AUTOSAR XML (schema 4-1-3)
standard types defined: boolean, sint16, uint16, uint8
package /UAES/ASW/ApplicationDataTypes
  6 x app type, all with category=CURVE, sw-calibration-access=READ-WRITE, compu {identical}:
    Appl_HvacBlowr_ratLPMBlowrCnv_CUR: sw-calprm-axis-set={sw-axis-index=1, category=COM_AXIS, sw-axis-individual={compu {identical}, sw-max-axis-points=3, sw-min-axis-points=3, range raw 0..255}}, range raw 0..65535
    Appl_HvacBlowr_ratPWMBlowrCnv_CUR: sw-calprm-axis-set={sw-axis-index=1, category=COM_AXIS, sw-axis-individual={compu {identical}, sw-max-axis-points=3, sw-min-axis-points=3, range raw 0..255}}, range raw 0..255
    Appl_HvacBlowr_ratReLPMBlowrCnv_CUR: sw-calprm-axis-set={sw-axis-index=1, category=COM_AXIS, sw-axis-individual={compu {identical}, sw-max-axis-points=3, sw-min-axis-points=3, range raw 0..255}}, range raw 0..65535
    Appl_HvacBlowr_ratRePWMBlowrCnv_CUR: sw-calprm-axis-set={sw-axis-index=1, category=COM_AXIS, sw-axis-individual={compu {identical}, sw-max-axis-points=3, sw-min-axis-points=3, range raw 0..255}}, range raw 0..255
    Appl_HvacBlowr_stLvlLPMBlowrCnv_CUR: sw-calprm-axis-set={sw-axis-index=1, category=COM_AXIS, sw-axis-individual={compu {identical}, sw-max-axis-points=3, sw-min-axis-points=3, range raw 0..65535}}, range raw 0..255
    Appl_HvacBlowr_stLvlReLPMBlowrCnv_CUR: sw-calprm-axis-set={sw-axis-index=1, category=COM_AXIS, sw-axis-individual={compu {identical}, sw-max-axis-points=3, sw-min-axis-points=3, range raw 0..65535}}, range raw 0..255
package /UAES/ASW/CompuMethods
  compu method CM_boolean: 0=FALSE, 1=TRUE
package /UAES/ASW/DataConstrs
  range DC_boolean: raw 0..1
  range DC_sint16: raw -32768..32767
package /UAES/ASW/DataTypeMappingSets
  data type mapping set DTMS_HvacBlowr_Ctrl
    data-type-maps:
      application-data-type=Appl_HvacBlowr_ratLPMBlowrCnv_CUR, implementation-data-type=HvacBlowr_ratLPMBlowrCnv_CUR_Type
      application-data-type=Appl_HvacBlowr_ratPWMBlowrCnv_CUR, implementation-data-type=HvacBlowr_ratPWMBlowrCnv_CUR_Type
      application-data-type=Appl_HvacBlowr_ratReLPMBlowrCnv_CUR, implementation-data-type=HvacBlowr_ratReLPMBlowrCnv_CUR_Type
      application-data-type=Appl_HvacBlowr_ratRePWMBlowrCnv_CUR, implementation-data-type=HvacBlowr_ratRePWMBlowrCnv_CUR_Type
      application-data-type=Appl_HvacBlowr_stLvlLPMBlowrCnv_CUR, implementation-data-type=HvacBlowr_stLvlLPMBlowrCnv_CUR_Type
      application-data-type=Appl_HvacBlowr_stLvlReLPMBlowrCnv_CUR, implementation-data-type=HvacBlowr_stLvlReLPMBlowrCnv_CUR_Type
package /UAES/ASW/ImplementationDataTypes
  8 x impl type:
    HvacBlowr_ratLPMBlowrCnv_CUR_Type: category=STRUCTURE
      element N1: implementation-data-type=uint8
      element BP1: implementation-data-type=rt_Array_uint8_3
      element Table: implementation-data-type=rt_Array_uint16_3
    HvacBlowr_ratPWMBlowrCnv_CUR_Type: category=STRUCTURE
      element N1: implementation-data-type=uint8
      element BP1: implementation-data-type=rt_Array_uint8_3
      element Table: implementation-data-type=rt_Array_uint8_3
    HvacBlowr_ratReLPMBlowrCnv_CUR_Type: category=STRUCTURE
      element N1: implementation-data-type=uint8
      element BP1: implementation-data-type=rt_Array_uint8_3
      element Table: implementation-data-type=rt_Array_uint16_3
    HvacBlowr_ratRePWMBlowrCnv_CUR_Type: category=STRUCTURE
      element N1: implementation-data-type=uint8
      element BP1: implementation-data-type=rt_Array_uint8_3
      element Table: implementation-data-type=rt_Array_uint8_3
    HvacBlowr_stLvlLPMBlowrCnv_CUR_Type: category=STRUCTURE
      element N1: implementation-data-type=uint16
      element BP1: implementation-data-type=rt_Array_uint16_3
      element Table: implementation-data-type=rt_Array_uint8_3
    HvacBlowr_stLvlReLPMBlowrCnv_CUR_Type: category=STRUCTURE
      element N1: implementation-data-type=uint16
      element BP1: implementation-data-type=rt_Array_uint16_3
      element Table: implementation-data-type=rt_Array_uint8_3
    rt_Array_uint16_3: category=ARRAY
      element rt_Array_uint16_3: array-size=3, array-size-semantics=FIXED-SIZE, implementation-data-type=uint16
    rt_Array_uint8_3: category=ARRAY
      element rt_Array_uint8_3: array-size=3, array-size-semantics=FIXED-SIZE, implementation-data-type=uint8
package /UAES/ASW/ImplementationDataTypes/Ground
  9 x constant specification:
    HvacBlowr_freqPWMBlowr1_C: value-spec=BLOWER_FREQUENCY_SPEC1:500
    HvacBlowr_freqPWMBlowr2_C: value-spec=BLOWER_FREQUENCY_SPEC1:100
    HvacBlowr_freqPWMBlowr3_C: value-spec=BLOWER_FREQUENCY_SPEC1:35
    HvacBlowr_ratLPMBlowrCnv_CUR: value-spec=fields=[N:3, X:[0, 1, 31], Y:[0, 230, 950]]
    HvacBlowr_ratPWMBlowrCnv_CUR: value-spec=fields=[N:3, X:[0, 1, 31], Y:[0, 23, 85]]
    HvacBlowr_ratReLPMBlowrCnv_CUR: value-spec=fields=[N:3, X:[0, 1, 31], Y:[0, 230, 950]]
    HvacBlowr_ratRePWMBlowrCnv_CUR: value-spec=fields=[N:3, X:[0, 1, 31], Y:[0, 23, 85]]
    HvacBlowr_stLvlLPMBlowrCnv_CUR: value-spec=fields=[N:3, X:[0, 350, 1350], Y:[0, 1, 31]]
    HvacBlowr_stLvlReLPMBlowrCnv_CUR: value-spec=fields=[N:3, X:[0, 350, 1350], Y:[0, 1, 31]]
package /UAES/ASW/PortInterfaces
  client server interface IoHwAb_IoSigAdc
    operation Adc_Get: possible-error=E_NOT_OK
      arg id_u16: type=uint16, direction=IN, server-argument-impl-policy=USE-ARGUMENT-TYPE
      arg val_s16: type=sint16, direction=OUT, server-argument-impl-policy=USE-ARGUMENT-TYPE
    operation AdcFac_Get: possible-error=E_NOT_OK
      arg id_u16: type=uint16, direction=IN, server-argument-impl-policy=USE-ARGUMENT-TYPE
      arg val_s16: type=sint16, direction=OUT, server-argument-impl-policy=USE-ARGUMENT-TYPE
    operation AdcVRMBatt_Get: possible-error=E_NOT_OK
      arg id_u16: type=uint16, direction=IN, server-argument-impl-policy=USE-ARGUMENT-TYPE
      arg val_u8: type=uint8, direction=OUT, server-argument-impl-policy=USE-ARGUMENT-TYPE
    error E_NOT_OK: error-code=1
  20 x sender receiver interface:
    gCFG_u8BlowrCtrlFreqTyp: invalidation-policy{data-element=gCFG_u8BlowrCtrlFreqTyp/Val, handle-invalid=DONT-INVALIDATE}
      data Val: sw-calibration-access=READ-ONLY, type=uint8
    gCFG_u8BlowrCtrlTyp: invalidation-policy{data-element=gCFG_u8BlowrCtrlTyp/Val, handle-invalid=DONT-INVALIDATE}
      data Val: sw-calibration-access=READ-ONLY, type=uint8
    gCFG_u8ReBlowrCtrlFreqTyp: invalidation-policy{data-element=gCFG_u8ReBlowrCtrlFreqTyp/Val, handle-invalid=DONT-INVALIDATE}
      data Val: sw-calibration-access=READ-ONLY, type=uint8
    gCFG_u8ReBlowrCtrlTyp: invalidation-policy{data-element=gCFG_u8ReBlowrCtrlTyp/Val, handle-invalid=DONT-INVALIDATE}
      data Val: sw-calibration-access=READ-ONLY, type=uint8
    gPRM_u8VehicleTypeCfg: invalidation-policy{data-element=gPRM_u8VehicleTypeCfg/Val, handle-invalid=DONT-INVALIDATE}
      data Val: sw-calibration-access=READ-ONLY, range raw 0..255, type=uint8
    HvacBlowr_bLPMBlowrEna: invalidation-policy{data-element=HvacBlowr_bLPMBlowrEna/Val, handle-invalid=DONT-INVALIDATE}
      data Val: sw-calibration-access=READ-ONLY, type=boolean
    HvacBlowr_bReLPMBlowrEna: invalidation-policy{data-element=HvacBlowr_bReLPMBlowrEna/Val, handle-invalid=DONT-INVALIDATE}
      data Val: sw-calibration-access=READ-ONLY, type=boolean
    HvacBlowr_bUdsTrigFrnt: invalidation-policy{data-element=HvacBlowr_bUdsTrigFrnt/Val, handle-invalid=DONT-INVALIDATE}
      data Val: sw-calibration-access=READ-ONLY, type=boolean
    HvacBlowr_freqPWMBlowr: invalidation-policy{data-element=HvacBlowr_freqPWMBlowr/Val, handle-invalid=DONT-INVALIDATE}
      data Val: sw-calibration-access=READ-ONLY, type=uint16
    HvacBlowr_freqRePWMBlowr: invalidation-policy{data-element=HvacBlowr_freqRePWMBlowr/Val, handle-invalid=DONT-INVALIDATE}
      data Val: sw-calibration-access=READ-ONLY, type=uint16
    HvacBlowr_ratLPMBlowr: invalidation-policy{data-element=HvacBlowr_ratLPMBlowr/Val, handle-invalid=DONT-INVALIDATE}
      data Val: sw-calibration-access=READ-ONLY, type=uint16
    HvacBlowr_ratPWMBlowr: invalidation-policy{data-element=HvacBlowr_ratPWMBlowr/Val, handle-invalid=DONT-INVALIDATE}
      data Val: sw-calibration-access=READ-ONLY, type=uint16
    HvacBlowr_ratReLPMBlowr: invalidation-policy{data-element=HvacBlowr_ratReLPMBlowr/Val, handle-invalid=DONT-INVALIDATE}
      data Val: sw-calibration-access=READ-ONLY, type=uint16
    HvacBlowr_ratRePWMBlowr: invalidation-policy{data-element=HvacBlowr_ratRePWMBlowr/Val, handle-invalid=DONT-INVALIDATE}
      data Val: sw-calibration-access=READ-ONLY, type=uint16
    HvacBlowr_stReWindExitSpdLvl: invalidation-policy{data-element=HvacBlowr_stReWindExitSpdLvl/Val, handle-invalid=DONT-INVALIDATE}
      data Val: sw-calibration-access=READ-ONLY, type=uint8
    HvacBlowr_stReWindExitSpdLvlAct: invalidation-policy{data-element=HvacBlowr_stReWindExitSpdLvlAct/Val, handle-invalid=DONT-INVALIDATE}
      data Val: sw-calibration-access=READ-ONLY, type=uint8
    HvacBlowr_stSpdLvlUdsFrnt: invalidation-policy{data-element=HvacBlowr_stSpdLvlUdsFrnt/Val, handle-invalid=DONT-INVALIDATE}
      data Val: sw-calibration-access=READ-ONLY, type=uint8
    HvacBlowr_stWindExitSpdLvl: invalidation-policy{data-element=HvacBlowr_stWindExitSpdLvl/Val, handle-invalid=DONT-INVALIDATE}
      data Val: sw-calibration-access=READ-ONLY, type=uint8
    HvacBlowr_stWindExitSpdLvlAct: invalidation-policy{data-element=HvacBlowr_stWindExitSpdLvlAct/Val, handle-invalid=DONT-INVALIDATE}
      data Val: sw-calibration-access=READ-ONLY, type=uint8
    HvacBlowr_uRawLPMFb: invalidation-policy{data-element=HvacBlowr_uRawLPMFb/Val, handle-invalid=DONT-INVALIDATE}
      data Val: sw-calibration-access=READ-ONLY, type=uint16
package /UAES/ASW/SwAddrMethods
  sw addr method CALDATA
package /UAES/ASW/SwComponentTypes
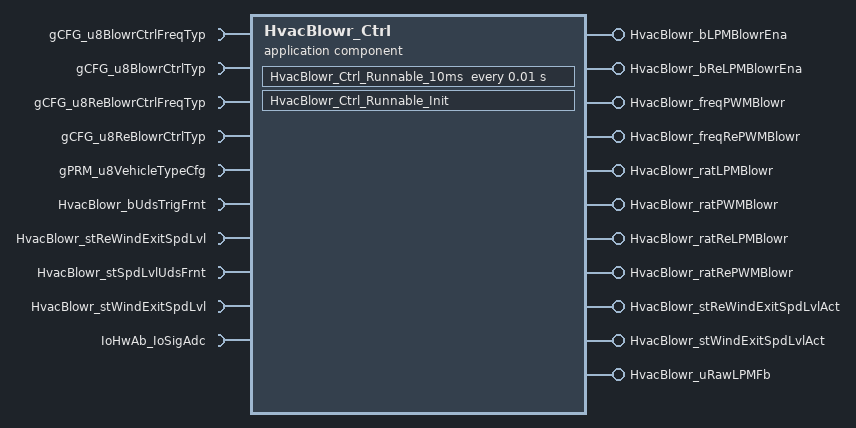
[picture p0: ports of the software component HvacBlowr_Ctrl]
  application sw component type HvacBlowr_Ctrl
    11 x provide port:
      HvacBlowr_bLPMBlowrEna: nonqueued-sender-com-spec{data-element=HvacBlowr_bLPMBlowrEna/Val, init-value=0}, provided-interface=HvacBlowr_bLPMBlowrEna
      HvacBlowr_bReLPMBlowrEna: nonqueued-sender-com-spec{data-element=HvacBlowr_bReLPMBlowrEna/Val, init-value=0}, provided-interface=HvacBlowr_bReLPMBlowrEna
      HvacBlowr_freqPWMBlowr: nonqueued-sender-com-spec{data-element=HvacBlowr_freqPWMBlowr/Val, init-value=0}, provided-interface=HvacBlowr_freqPWMBlowr
      HvacBlowr_freqRePWMBlowr: nonqueued-sender-com-spec{data-element=HvacBlowr_freqRePWMBlowr/Val, init-value=0}, provided-interface=HvacBlowr_freqRePWMBlowr
      HvacBlowr_ratLPMBlowr: nonqueued-sender-com-spec{data-element=HvacBlowr_ratLPMBlowr/Val, init-value=0}, provided-interface=HvacBlowr_ratLPMBlowr
      HvacBlowr_ratPWMBlowr: nonqueued-sender-com-spec{data-element=HvacBlowr_ratPWMBlowr/Val, init-value=0}, provided-interface=HvacBlowr_ratPWMBlowr
      HvacBlowr_ratReLPMBlowr: nonqueued-sender-com-spec{data-element=HvacBlowr_ratReLPMBlowr/Val, init-value=0}, provided-interface=HvacBlowr_ratReLPMBlowr
      HvacBlowr_ratRePWMBlowr: nonqueued-sender-com-spec{data-element=HvacBlowr_ratRePWMBlowr/Val, init-value=0}, provided-interface=HvacBlowr_ratRePWMBlowr
      HvacBlowr_stReWindExitSpdLvlAct: nonqueued-sender-com-spec{data-element=HvacBlowr_stReWindExitSpdLvlAct/Val, init-value=0}, provided-interface=HvacBlowr_stReWindExitSpdLvlAct
      HvacBlowr_stWindExitSpdLvlAct: nonqueued-sender-com-spec{data-element=HvacBlowr_stWindExitSpdLvlAct/Val, init-value=0}, provided-interface=HvacBlowr_stWindExitSpdLvlAct
      HvacBlowr_uRawLPMFb: nonqueued-sender-com-spec{data-element=HvacBlowr_uRawLPMFb/Val, init-value=0}, provided-interface=HvacBlowr_uRawLPMFb
    10 x require port:
      gCFG_u8BlowrCtrlFreqTyp: nonqueued-receiver-com-spec{data-element=gCFG_u8BlowrCtrlFreqTyp/Val, filter=data-filter-type=ALWAYS, init-value=0}, required-interface=gCFG_u8BlowrCtrlFreqTyp
      gCFG_u8BlowrCtrlTyp: nonqueued-receiver-com-spec{data-element=gCFG_u8BlowrCtrlTyp/Val, filter=data-filter-type=ALWAYS, init-value=0}, required-interface=gCFG_u8BlowrCtrlTyp
      gCFG_u8ReBlowrCtrlFreqTyp: nonqueued-receiver-com-spec{data-element=gCFG_u8ReBlowrCtrlFreqTyp/Val, filter=data-filter-type=ALWAYS, init-value=0}, required-interface=gCFG_u8ReBlowrCtrlFreqTyp
      gCFG_u8ReBlowrCtrlTyp: nonqueued-receiver-com-spec{data-element=gCFG_u8ReBlowrCtrlTyp/Val, filter=data-filter-type=ALWAYS, init-value=0}, required-interface=gCFG_u8ReBlowrCtrlTyp
      gPRM_u8VehicleTypeCfg: nonqueued-receiver-com-spec{data-element=gPRM_u8VehicleTypeCfg/Val, filter=data-filter-type=ALWAYS, init-value=0}, required-interface=gPRM_u8VehicleTypeCfg
      HvacBlowr_bUdsTrigFrnt: nonqueued-receiver-com-spec{data-element=HvacBlowr_bUdsTrigFrnt/Val, filter=data-filter-type=ALWAYS, init-value=0}, required-interface=HvacBlowr_bUdsTrigFrnt
      HvacBlowr_stReWindExitSpdLvl: nonqueued-receiver-com-spec{data-element=HvacBlowr_stReWindExitSpdLvl/Val, filter=data-filter-type=ALWAYS, init-value=0}, required-interface=HvacBlowr_stReWindExitSpdLvl
      HvacBlowr_stSpdLvlUdsFrnt: nonqueued-receiver-com-spec{data-element=HvacBlowr_stSpdLvlUdsFrnt/Val, filter=data-filter-type=ALWAYS, init-value=0}, required-interface=HvacBlowr_stSpdLvlUdsFrnt
      HvacBlowr_stWindExitSpdLvl: nonqueued-receiver-com-spec{data-element=HvacBlowr_stWindExitSpdLvl/Val, filter=data-filter-type=ALWAYS, init-value=0}, required-interface=HvacBlowr_stWindExitSpdLvl
      IoHwAb_IoSigAdc: required-com-specs=[Adc_Get, AdcFac_Get, AdcVRMBatt_Get], required-interface=IoHwAb_IoSigAdc
    behavior HvacBlowr_Ctrl_InternalBehavior: data-type-mapping=DTMS_HvacBlowr_Ctrl
      timing event TMT_HvacBlowr_Ctrl_Runnable_10ms: start-on-event=HvacBlowr_Ctrl_Runnable_10ms, period=0.01
      init event HvacBlowr_Ctrl_InitEvent: start-on-event=HvacBlowr_Ctrl_Runnable_Init
      runnable HvacBlowr_Ctrl_Runnable_10ms
        data-receive-point-by-arguments:
          9 x access:
            REC_gCFG_u8BlowrCtrlFreqTyp_Val: accessed-variable=gCFG_u8BlowrCtrlFreqTyp.Val
            REC_gCFG_u8BlowrCtrlTyp_Val: accessed-variable=gCFG_u8BlowrCtrlTyp.Val
            REC_gCFG_u8ReBlowrCtrlFreqTyp_Val: accessed-variable=gCFG_u8ReBlowrCtrlFreqTyp.Val
            REC_gCFG_u8ReBlowrCtrlTyp_Val: accessed-variable=gCFG_u8ReBlowrCtrlTyp.Val
            REC_gPRM_u8VehicleTypeCfg_Val: accessed-variable=gPRM_u8VehicleTypeCfg.Val
            REC_HvacBlowr_bUdsTrigFrnt_Val: accessed-variable=HvacBlowr_bUdsTrigFrnt.Val
            REC_HvacBlowr_stReWindExitSpdLvl_Val: accessed-variable=HvacBlowr_stReWindExitSpdLvl.Val
            REC_HvacBlowr_stSpdLvlUdsFrnt_Val: accessed-variable=HvacBlowr_stSpdLvlUdsFrnt.Val
            REC_HvacBlowr_stWindExitSpdLvl_Val: accessed-variable=HvacBlowr_stWindExitSpdLvl.Val
        data-send-points:
          11 x access:
            SEND_HvacBlowr_bLPMBlowrEna_Val: accessed-variable=HvacBlowr_bLPMBlowrEna.Val
            SEND_HvacBlowr_bReLPMBlowrEna_Val: accessed-variable=HvacBlowr_bReLPMBlowrEna.Val
            SEND_HvacBlowr_freqPWMBlowr_Val: accessed-variable=HvacBlowr_freqPWMBlowr.Val
            SEND_HvacBlowr_freqRePWMBlowr_Val: accessed-variable=HvacBlowr_freqRePWMBlowr.Val
            SEND_HvacBlowr_ratLPMBlowr_Val: accessed-variable=HvacBlowr_ratLPMBlowr.Val
            SEND_HvacBlowr_ratPWMBlowr_Val: accessed-variable=HvacBlowr_ratPWMBlowr.Val
            SEND_HvacBlowr_ratReLPMBlowr_Val: accessed-variable=HvacBlowr_ratReLPMBlowr.Val
            SEND_HvacBlowr_ratRePWMBlowr_Val: accessed-variable=HvacBlowr_ratRePWMBlowr.Val
            SEND_HvacBlowr_stReWindExitSpdLvlAct_Val: accessed-variable=HvacBlowr_stReWindExitSpdLvlAct.Val
            SEND_HvacBlowr_stWindExitSpdLvlAct_Val: accessed-variable=HvacBlowr_stWindExitSpdLvlAct.Val
            SEND_HvacBlowr_uRawLPMFb_Val: accessed-variable=HvacBlowr_uRawLPMFb.Val
        9 x parameter access:
          PA_HvacBlowr_freqPWMBlowr{1..3}_C: accessed-parameter=HvacBlowr_freqPWMBlowr{1..3}_C
          PA_HvacBlowr_ratLPMBlowrCnv_CUR: accessed-parameter=HvacBlowr_ratLPMBlowrCnv_CUR
          PA_HvacBlowr_ratPWMBlowrCnv_CUR: accessed-parameter=HvacBlowr_ratPWMBlowrCnv_CUR
          PA_HvacBlowr_ratReLPMBlowrCnv_CUR: accessed-parameter=HvacBlowr_ratReLPMBlowrCnv_CUR
          PA_HvacBlowr_ratRePWMBlowrCnv_CUR: accessed-parameter=HvacBlowr_ratRePWMBlowrCnv_CUR
          PA_HvacBlowr_stLvlLPMBlowrCnv_CUR: accessed-parameter=HvacBlowr_stLvlLPMBlowrCnv_CUR
          PA_HvacBlowr_stLvlReLPMBlowrCnv_CUR: accessed-parameter=HvacBlowr_stLvlReLPMBlowrCnv_CUR
        sync call SC_IoHwAb_IoSigAdc_AdcFac_Get: operation=IoHwAb_IoSigAdc.AdcFac_Get, timeout=0
      runnable HvacBlowr_Ctrl_Runnable_Init
        data-receive-point-by-arguments:
          9 x access:
            REC_gCFG_u8BlowrCtrlFreqTyp_Val: accessed-variable=gCFG_u8BlowrCtrlFreqTyp.Val
            REC_gCFG_u8BlowrCtrlTyp_Val: accessed-variable=gCFG_u8BlowrCtrlTyp.Val
            REC_gCFG_u8ReBlowrCtrlFreqTyp_Val: accessed-variable=gCFG_u8ReBlowrCtrlFreqTyp.Val
            REC_gCFG_u8ReBlowrCtrlTyp_Val: accessed-variable=gCFG_u8ReBlowrCtrlTyp.Val
            REC_gPRM_u8VehicleTypeCfg_Val: accessed-variable=gPRM_u8VehicleTypeCfg.Val
            REC_HvacBlowr_bUdsTrigFrnt_Val: accessed-variable=HvacBlowr_bUdsTrigFrnt.Val
            REC_HvacBlowr_stReWindExitSpdLvl_Val: accessed-variable=HvacBlowr_stReWindExitSpdLvl.Val
            REC_HvacBlowr_stSpdLvlUdsFrnt_Val: accessed-variable=HvacBlowr_stSpdLvlUdsFrnt.Val
            REC_HvacBlowr_stWindExitSpdLvl_Val: accessed-variable=HvacBlowr_stWindExitSpdLvl.Val
        data-send-points:
          11 x access:
            SEND_HvacBlowr_bLPMBlowrEna_Val: accessed-variable=HvacBlowr_bLPMBlowrEna.Val
            SEND_HvacBlowr_bReLPMBlowrEna_Val: accessed-variable=HvacBlowr_bReLPMBlowrEna.Val
            SEND_HvacBlowr_freqPWMBlowr_Val: accessed-variable=HvacBlowr_freqPWMBlowr.Val
            SEND_HvacBlowr_freqRePWMBlowr_Val: accessed-variable=HvacBlowr_freqRePWMBlowr.Val
            SEND_HvacBlowr_ratLPMBlowr_Val: accessed-variable=HvacBlowr_ratLPMBlowr.Val
            SEND_HvacBlowr_ratPWMBlowr_Val: accessed-variable=HvacBlowr_ratPWMBlowr.Val
            SEND_HvacBlowr_ratReLPMBlowr_Val: accessed-variable=HvacBlowr_ratReLPMBlowr.Val
            SEND_HvacBlowr_ratRePWMBlowr_Val: accessed-variable=HvacBlowr_ratRePWMBlowr.Val
            SEND_HvacBlowr_stReWindExitSpdLvlAct_Val: accessed-variable=HvacBlowr_stReWindExitSpdLvlAct.Val
            SEND_HvacBlowr_stWindExitSpdLvlAct_Val: accessed-variable=HvacBlowr_stWindExitSpdLvlAct.Val
            SEND_HvacBlowr_uRawLPMFb_Val: accessed-variable=HvacBlowr_uRawLPMFb.Val
        9 x parameter access:
          PA_HvacBlowr_freqPWMBlowr{1..3}_C: accessed-parameter=HvacBlowr_freqPWMBlowr{1..3}_C
          PA_HvacBlowr_ratLPMBlowrCnv_CUR: accessed-parameter=HvacBlowr_ratLPMBlowrCnv_CUR
          PA_HvacBlowr_ratPWMBlowrCnv_CUR: accessed-parameter=HvacBlowr_ratPWMBlowrCnv_CUR
          PA_HvacBlowr_ratReLPMBlowrCnv_CUR: accessed-parameter=HvacBlowr_ratReLPMBlowrCnv_CUR
          PA_HvacBlowr_ratRePWMBlowrCnv_CUR: accessed-parameter=HvacBlowr_ratRePWMBlowrCnv_CUR
          PA_HvacBlowr_stLvlLPMBlowrCnv_CUR: accessed-parameter=HvacBlowr_stLvlLPMBlowrCnv_CUR
          PA_HvacBlowr_stLvlReLPMBlowrCnv_CUR: accessed-parameter=HvacBlowr_stLvlReLPMBlowrCnv_CUR
        sync call SC_IoHwAb_IoSigAdc_AdcFac_Get: operation=IoHwAb_IoSigAdc.AdcFac_Get, timeout=0
      shared-parameters:
        9 x parameter data prototype, all with sw-addr-method=CALDATA, sw-calibration-access=READ-WRITE:
          HvacBlowr_freqPWMBlowr1_C: type=uint16, init-value=constant-reference={short-label=BLOWER_FREQUENCY_SPEC1, constant=HvacBlowr_freqPWMBlowr1_C}
          HvacBlowr_freqPWMBlowr2_C: type=uint16, init-value=constant-reference={short-label=BLOWER_FREQUENCY_SPEC2, constant=HvacBlowr_freqPWMBlowr2_C}
          HvacBlowr_freqPWMBlowr3_C: type=uint16, init-value=constant-reference={short-label=BLOWER_FREQUENCY_SPEC2, constant=HvacBlowr_freqPWMBlowr3_C}
          HvacBlowr_ratLPMBlowrCnv_CUR: type=Appl_HvacBlowr_ratLPMBlowrCnv_CUR, init-value=constant-reference={short-label=HVAC_ratLPMBlowerCnv_CUR, constant=HvacBlowr_ratLPMBlowrCnv_CUR}
          HvacBlowr_ratPWMBlowrCnv_CUR: type=Appl_HvacBlowr_ratPWMBlowrCnv_CUR, init-value=constant-reference={short-label=HVAC_ratPWMBlowerCnv_CUR, constant=HvacBlowr_ratPWMBlowrCnv_CUR}
          HvacBlowr_ratReLPMBlowrCnv_CUR: type=Appl_HvacBlowr_ratReLPMBlowrCnv_CUR, init-value=constant-reference=HvacBlowr_ratReLPMBlowrCnv_CUR
          HvacBlowr_ratRePWMBlowrCnv_CUR: type=Appl_HvacBlowr_ratRePWMBlowrCnv_CUR, init-value=constant-reference={short-label=HVAC_ratPWMBlowerCnv_CUR, constant=HvacBlowr_ratRePWMBlowrCnv_CUR}
          HvacBlowr_stLvlLPMBlowrCnv_CUR: type=Appl_HvacBlowr_stLvlLPMBlowrCnv_CUR, init-value=constant-reference={short-label=HVAC_stLvlLPMBlowerCnv_CUR, constant=HvacBlowr_stLvlLPMBlowrCnv_CUR}
          HvacBlowr_stLvlReLPMBlowrCnv_CUR: type=Appl_HvacBlowr_stLvlReLPMBlowrCnv_CUR, init-value=constant-reference=HvacBlowr_stLvlReLPMBlowrCnv_CUR
  swc implementation HvacBlowr_Ctrl_Implementation: behavior=HvacBlowr_Ctrl_InternalBehavior
    code-descriptors:
      code Default: artifact-descriptors=autosar-engineering-object={short-label=Default, category=SWSRC}
package /UAES/ASW/Units
  unit NoUnit: factor-si-to-unit=1, offset-si-to-unit=0
